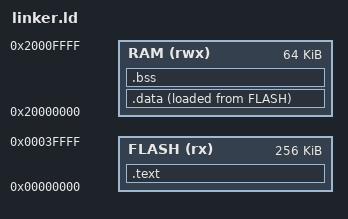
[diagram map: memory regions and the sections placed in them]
ENTRY(Reset_Handler)

MEMORY
{
    FLASH (rx)  : ORIGIN = 0x00000000, LENGTH = 256K
    RAM   (rwx) : ORIGIN = 0x20000000, LENGTH = 64K
}

SECTIONS
{
    .text : {
        KEEP(*(.isr_vector))
        *(.text*)
        *(.rodata*)
        . = ALIGN(4);
    } > FLASH

    _sidata = LOADADDR(.data);
    .data : {
        . = ALIGN(4);
        _sdata = .;
        *(.data*)
        . = ALIGN(4);
        _edata = .;
    } > RAM AT > FLASH

    .bss (NOLOAD) : {
        . = ALIGN(4);
        _sbss = .;
        *(.bss*)
        *(COMMON)
        . = ALIGN(4);
        _ebss = .;
    } > RAM

    _stack_top = ORIGIN(RAM) + LENGTH(RAM);
}
